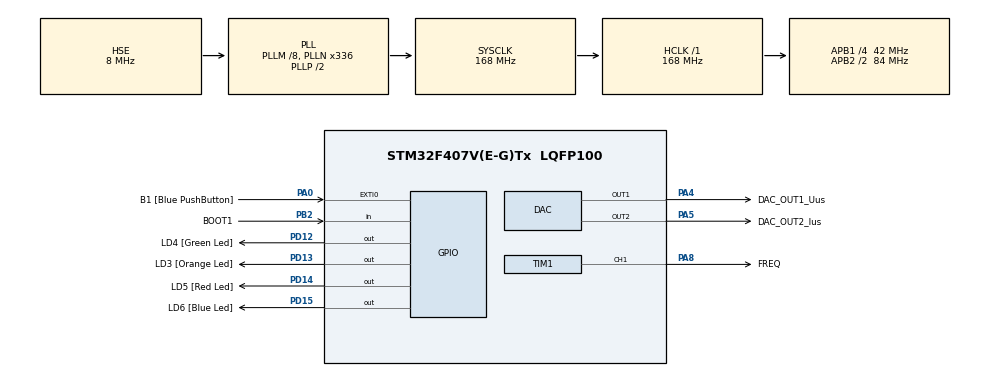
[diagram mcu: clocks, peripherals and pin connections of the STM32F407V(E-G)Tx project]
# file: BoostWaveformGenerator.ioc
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DAC.DAC_Trigger=DAC_TRIGGER_NONE
DAC.DAC_Trigger2=DAC_TRIGGER_T6_TRGO
Dma.DAC2.0.Direction=DMA_MEMORY_TO_PERIPH
Dma.DAC2.0.FIFOMode=DMA_FIFOMODE_DISABLE
Dma.DAC2.0.Instance=DMA1_Stream6
Dma.DAC2.0.MemDataAlignment=DMA_MDATAALIGN_HALFWORD
Dma.DAC2.0.MemInc=DMA_MINC_ENABLE
Dma.DAC2.0.Mode=DMA_CIRCULAR
Dma.DAC2.0.PeriphDataAlignment=DMA_PDATAALIGN_HALFWORD
Dma.DAC2.0.PeriphInc=DMA_PINC_DISABLE
Dma.DAC2.0.Priority=DMA_PRIORITY_LOW
Dma.Request0=DAC2
Mcu.Family=STM32F4
Mcu.Name=STM32F407V(E-G)Tx
Mcu.Package=LQFP100
Mcu.UserConstants=TIM6_APB1_PSC,8400;TIM6_ARR_100MS,1000
NVIC.DMA1_Stream6_IRQn=true\:0\:0\:false\:false\:true\:false
NVIC.PriorityGroup=NVIC_PRIORITYGROUP_0
NVIC.TIM6_DAC_IRQn=true\:0\:0\:false\:false\:true\:true
PA0-WKUP.GPIO_Label=B1 [Blue PushButton]
PA0-WKUP.GPIO_ModeDefaultEXTI=GPIO_MODE_EVT_RISING
PA0-WKUP.GPIO_PuPd=GPIO_NOPULL
PA0-WKUP.Signal=GPXTI0
PA13.GPIO_Label=SWDIO
PA13.Mode=Serial_Wire
PA13.Signal=SYS_JTMS-SWDIO
PA14.GPIO_Label=SWCLK
PA14.Mode=Serial_Wire
PA14.Signal=SYS_JTCK-SWCLK
PA4.GPIO_Label=DAC_OUT1_Uus
PA4.Signal=COMP_DAC1_group
PA5.GPIO_Label=DAC_OUT2_Ius
PA5.Signal=COMP_DAC2_group
PA8.GPIO_Label=FREQ
PA8.GPIO_Speed=GPIO_SPEED_FREQ_VERY_HIGH
PA8.Signal=S_TIM1_CH1
PB2.GPIO_Label=BOOT1
PB2.GPIO_Mode=GPIO_MODE_INPUT
PB2.GPIO_PuPd=GPIO_NOPULL
PB2.Signal=GPIO_Input
PB3.GPIO_Label=SWO
PB3.Signal=SYS_JTDO-SWO
PC14-OSC32_IN.GPIO_Label=PC14-OSC32_IN
PC14-OSC32_IN.Mode=LSE-External-Oscillator
PC14-OSC32_IN.Signal=RCC_OSC32_IN
PC15-OSC32_OUT.GPIO_Label=PC15-OSC32_OUT
PC15-OSC32_OUT.Mode=LSE-External-Oscillator
PC15-OSC32_OUT.Signal=RCC_OSC32_OUT
PD12.GPIO_Label=LD4 [Green Led]
PD12.GPIO_PuPd=GPIO_NOPULL
PD12.GPIO_Speed=GPIO_SPEED_FREQ_LOW
PD12.Signal=GPIO_Output
PD13.GPIO_Label=LD3 [Orange Led]
PD13.GPIO_PuPd=GPIO_NOPULL
PD13.GPIO_Speed=GPIO_SPEED_FREQ_LOW
PD13.Signal=GPIO_Output
PD14.GPIO_Label=LD5 [Red Led]
PD14.GPIO_PuPd=GPIO_NOPULL
PD14.GPIO_Speed=GPIO_SPEED_FREQ_LOW
PD14.Signal=GPIO_Output
PD15.GPIO_Label=LD6 [Blue Led]
PD15.GPIO_PuPd=GPIO_NOPULL
PD15.GPIO_Speed=GPIO_SPEED_FREQ_LOW
PD15.Signal=GPIO_Output
PH0-OSC_IN.GPIO_Label=PH0-OSC_IN
PH0-OSC_IN.Mode=HSE-External-Oscillator
PH0-OSC_IN.Signal=RCC_OSC_IN
PH1-OSC_OUT.GPIO_Label=PH1-OSC_OUT
PH1-OSC_OUT.Mode=HSE-External-Oscillator
PH1-OSC_OUT.Signal=RCC_OSC_OUT
ProjectManager.HeapSize=0x200
ProjectManager.StackSize=0x400
ProjectManager.TargetToolchain=TrueSTUDIO
RCC.48MHZClocksFreq_Value=48000000
RCC.AHBFreq_Value=168000000
RCC.APB1CLKDivider=RCC_HCLK_DIV4
RCC.APB1Freq_Value=42000000
RCC.APB1TimFreq_Value=84000000
RCC.APB2CLKDivider=RCC_HCLK_DIV2
RCC.APB2Freq_Value=84000000
RCC.APB2TimFreq_Value=168000000
RCC.CortexFreq_Value=168000000
RCC.HCLKFreq_Value=168000000
RCC.HSE_VALUE=8000000
RCC.HSI_VALUE=16000000
RCC.PLLM=8
RCC.PLLN=336
RCC.PLLQ=7
RCC.PLLSourceVirtual=RCC_PLLSOURCE_HSE
RCC.SYSCLKFreq_VALUE=168000000
RCC.SYSCLKSource=RCC_SYSCLKSOURCE_PLLCLK
RCC.VCOOutputFreq_Value=336000000
SH.COMP_DAC1_group.0=DAC_OUT1,DAC_OUT1
SH.COMP_DAC2_group.0=DAC_OUT2,DAC_OUT2
SH.S_TIM1_CH1.0=TIM1_CH1,PWM Generation1 CH1
TIM1.Channel-PWM\ Generation1\ CH1=TIM_CHANNEL_1
TIM1.Period=6109
TIM1.Pulse-PWM\ Generation1\ CH1=3000
TIM6.Period=TIM6_ARR_100MS
TIM6.Prescaler=TIM6_APB1_PSC
TIM6.TIM_MasterOutputTrigger=TIM_TRGO_UPDATE
VP_TIM6_VS_ClockSourceINT.Mode=Enable_Timer
board=STM32F4DISCOVERY

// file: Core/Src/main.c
/* USER CODE BEGIN Header */
/**
  ******************************************************************************
  * @file           : main.c
  * @brief          : Main program body
  ******************************************************************************
  ** This notice applies to any and all portions of this file
  * that are not between comment pairs USER CODE BEGIN and
  * USER CODE END. Other portions of this file, whether
  * inserted by the user or by software development tools
  * are owned by their respective copyright owners.
  *
  * COPYRIGHT(c) 2019 STMicroelectronics
  *
  * Redistribution and use in source and binary forms, with or without modification,
  * are permitted provided that the following conditions are met:
  *   1. Redistributions of source code must retain the above copyright notice,
  *      this list of conditions and the following disclaimer.
  *   2. Redistributions in binary form must reproduce the above copyright notice,
  *      this list of conditions and the following disclaimer in the documentation
  *      and/or other materials provided with the distribution.
  *   3. Neither the name of STMicroelectronics nor the names of its contributors
  *      may be used to endorse or promote products derived from this software
  *      without specific prior written permission.
  *
  * THIS SOFTWARE IS PROVIDED BY THE COPYRIGHT HOLDERS AND CONTRIBUTORS "AS IS"
  * AND ANY EXPRESS OR IMPLIED WARRANTIES, INCLUDING, BUT NOT LIMITED TO, THE
  * IMPLIED WARRANTIES OF MERCHANTABILITY AND FITNESS FOR A PARTICULAR PURPOSE ARE
  * DISCLAIMED. IN NO EVENT SHALL THE COPYRIGHT HOLDER OR CONTRIBUTORS BE LIABLE
  * FOR ANY DIRECT, INDIRECT, INCIDENTAL, SPECIAL, EXEMPLARY, OR CONSEQUENTIAL
  * DAMAGES (INCLUDING, BUT NOT LIMITED TO, PROCUREMENT OF SUBSTITUTE GOODS OR
  * SERVICES; LOSS OF USE, DATA, OR PROFITS; OR BUSINESS INTERRUPTION) HOWEVER
  * CAUSED AND ON ANY THEORY OF LIABILITY, WHETHER IN CONTRACT, STRICT LIABILITY,
  * OR TORT (INCLUDING NEGLIGENCE OR OTHERWISE) ARISING IN ANY WAY OUT OF THE USE
  * OF THIS SOFTWARE, EVEN IF ADVISED OF THE POSSIBILITY OF SUCH DAMAGE.
  *
  ******************************************************************************
  */
/* USER CODE END Header */

#include "main.h"
#include "dac.h"
#include "dma.h"
#include "tim.h"
#include "gpio.h"

void SystemClock_Config(void);

/* USER CODE BEGIN 0 */
extern TIM_HandleTypeDef htim1;
extern TIM_HandleTypeDef htim6;
/* USER CODE END 0 */

int main(void)
{

  /* MCU Configuration--------------------------------------------------------*/

  /* Reset of all peripherals, Initializes the Flash interface and the Systick. */
  HAL_Init();

  /* Configure the system clock */
  SystemClock_Config();

  /* Initialize all configured peripherals */
  MX_GPIO_Init();
  MX_DMA_Init();
  MX_DAC_Init();
  MX_TIM1_Init();
  MX_TIM6_Init();
  /* USER CODE BEGIN 2 */

  /*## Enable TIM1 peripheral counter to generate PWM (Freq signal) #########*/
  HAL_TIM_PWM_Start(&htim1, TIM_CHANNEL_1);

  /*## Enable DAC1 ##########################################################*/
  HAL_DAC_SetValue(&hdac, DAC_CHANNEL_1, DAC_ALIGN_12B_R, 1410);
  HAL_DAC_Start(&hdac, DAC_CHANNEL_1);

  /*## Prepare DMA1 to DAC1 transfers #######################################*/
  DAC_Start_DMA_WaveformUus27Ohms();

  /*## Enable TIM6 peripheral counter to generate the 100ms time base #######*/
  HAL_TIM_Base_Start_IT(&htim6);
  /* USER CODE END 2 */

  /* Infinite loop */
  while (1)
  {

  }
}

void SystemClock_Config(void)
{
  RCC_OscInitTypeDef RCC_OscInitStruct = {0};
  RCC_ClkInitTypeDef RCC_ClkInitStruct = {0};

  /**Configure the main internal regulator output voltage
  */
  __HAL_RCC_PWR_CLK_ENABLE();
  __HAL_PWR_VOLTAGESCALING_CONFIG(PWR_REGULATOR_VOLTAGE_SCALE1);
  /**Initializes the CPU, AHB and APB busses clocks
  */
  RCC_OscInitStruct.OscillatorType = RCC_OSCILLATORTYPE_HSE;
  RCC_OscInitStruct.HSEState = RCC_HSE_ON;
  RCC_OscInitStruct.PLL.PLLState = RCC_PLL_ON;
  RCC_OscInitStruct.PLL.PLLSource = RCC_PLLSOURCE_HSE;
  RCC_OscInitStruct.PLL.PLLM = 8;
  RCC_OscInitStruct.PLL.PLLN = 336;
  RCC_OscInitStruct.PLL.PLLP = RCC_PLLP_DIV2;
  RCC_OscInitStruct.PLL.PLLQ = 7;
  if (HAL_RCC_OscConfig(&RCC_OscInitStruct) != HAL_OK)
  {
    Error_Handler();
  }
  /**Initializes the CPU, AHB and APB busses clocks
  */
  RCC_ClkInitStruct.ClockType = RCC_CLOCKTYPE_HCLK|RCC_CLOCKTYPE_SYSCLK
                              |RCC_CLOCKTYPE_PCLK1|RCC_CLOCKTYPE_PCLK2;
  RCC_ClkInitStruct.SYSCLKSource = RCC_SYSCLKSOURCE_PLLCLK;
  RCC_ClkInitStruct.AHBCLKDivider = RCC_SYSCLK_DIV1;
  RCC_ClkInitStruct.APB1CLKDivider = RCC_HCLK_DIV4;
  RCC_ClkInitStruct.APB2CLKDivider = RCC_HCLK_DIV2;

  if (HAL_RCC_ClockConfig(&RCC_ClkInitStruct, FLASH_LATENCY_5) != HAL_OK)
  {
    Error_Handler();
  }
}

void Error_Handler(void)
{
}

/************************ (C) COPYRIGHT STMicroelectronics *****END OF FILE****/
